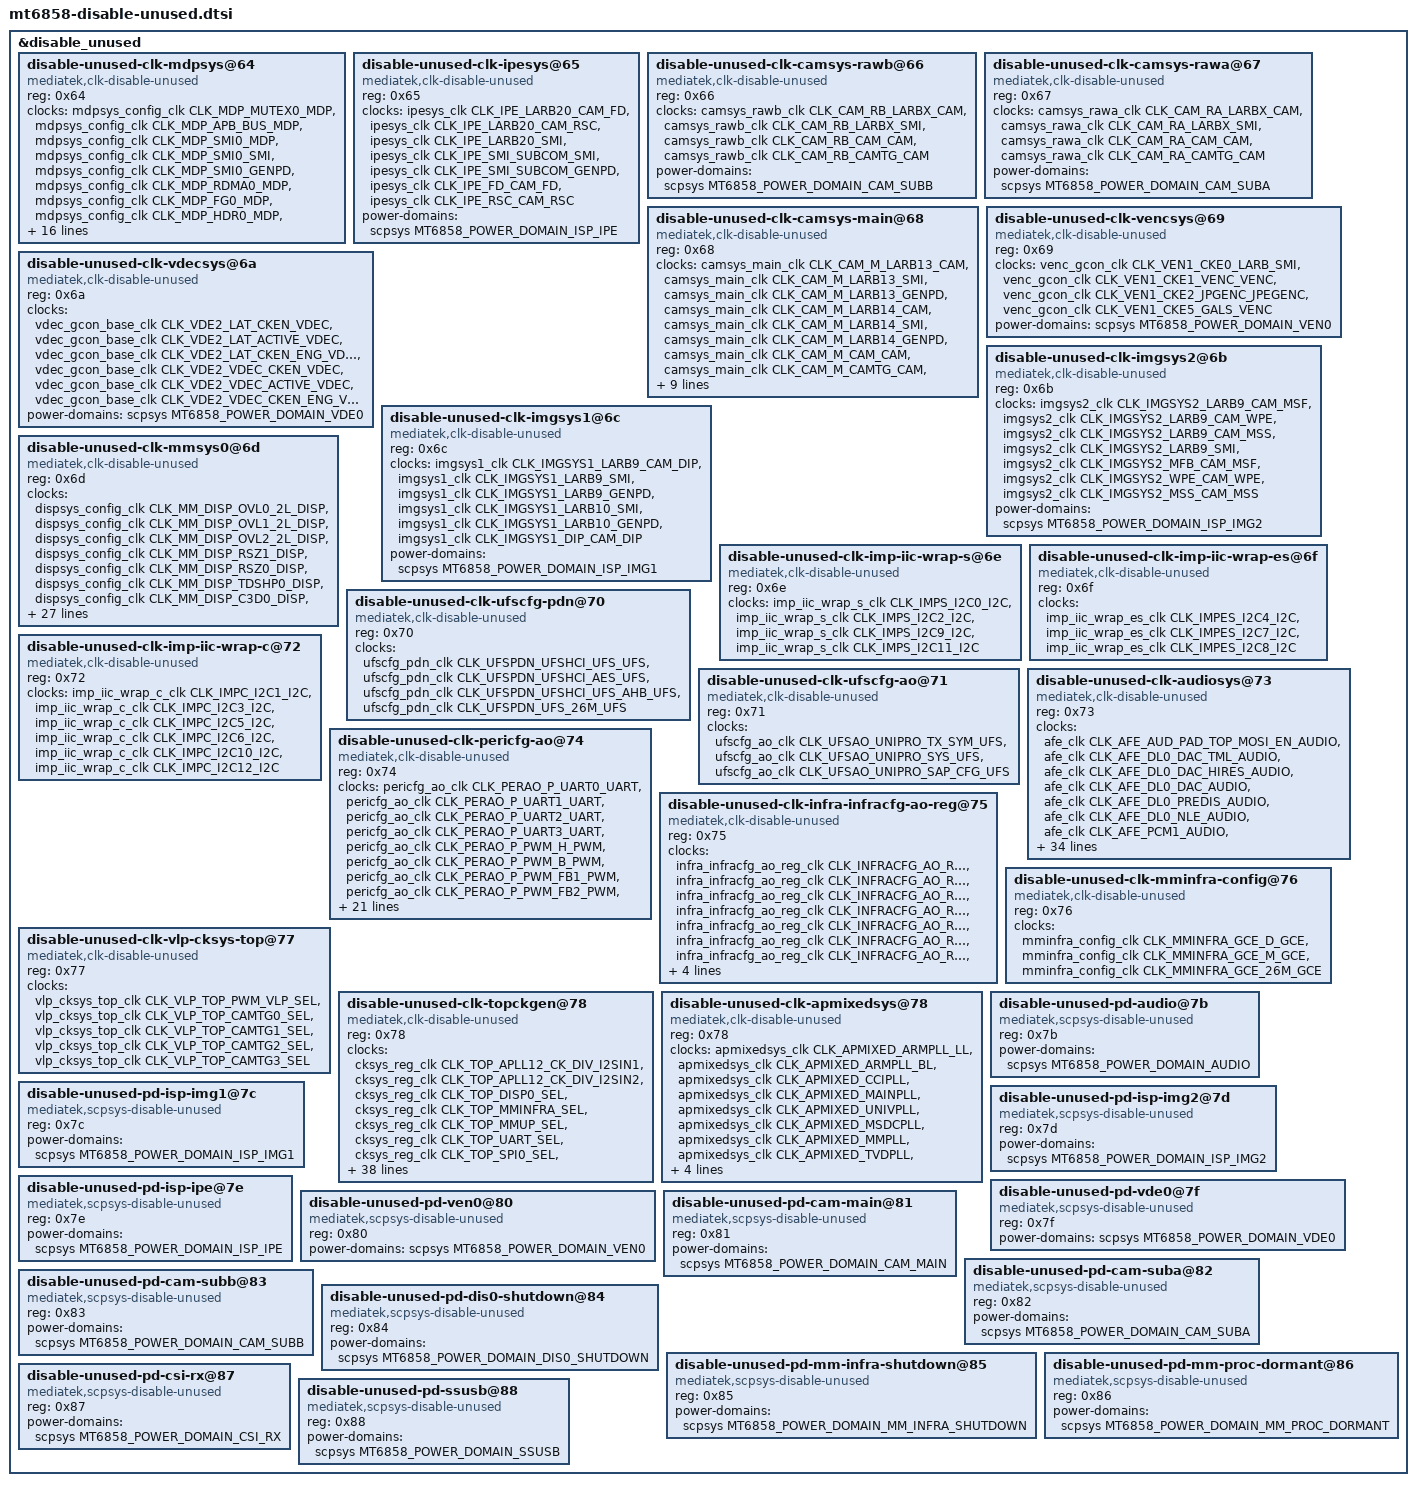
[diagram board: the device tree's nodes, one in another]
// SPDX-License-Identifier: (GPL-2.0 OR MIT)
/*
 * Copyright (C) 2025 MediaTek Inc.
 * Author: KY Liu <ky.liu@mediatek.com>
 */

&disable_unused {
	status = "okay";
	disable-unused-clk-mdpsys@64 {
		compatible = "mediatek,clk-disable-unused";
		reg = <0x64>;
		clocks =
			<&mdpsys_config_clk CLK_MDP_MUTEX0_MDP>,
			<&mdpsys_config_clk CLK_MDP_APB_BUS_MDP>,
			<&mdpsys_config_clk CLK_MDP_SMI0_MDP>,
			<&mdpsys_config_clk CLK_MDP_SMI0_SMI>,
			<&mdpsys_config_clk CLK_MDP_SMI0_GENPD>,
			<&mdpsys_config_clk CLK_MDP_RDMA0_MDP>,
			<&mdpsys_config_clk CLK_MDP_FG0_MDP>,
			<&mdpsys_config_clk CLK_MDP_HDR0_MDP>,
			<&mdpsys_config_clk CLK_MDP_AAL0_MDP>,
			<&mdpsys_config_clk CLK_MDP_RSZ0_MDP>,
			<&mdpsys_config_clk CLK_MDP_TDSHP0_MDP>,
			<&mdpsys_config_clk CLK_MDP_COLOR0_MDP>,
			<&mdpsys_config_clk CLK_MDP_WROT0_MDP>,
			<&mdpsys_config_clk CLK_MDP_FAKE_ENG0_MDP>,
			<&mdpsys_config_clk CLK_MDP_DLI_ASYNC0_MDP>,
			<&mdpsys_config_clk CLK_MDP_RSZ2_MDP>,
			<&mdpsys_config_clk CLK_MDP_WROT2_MDP>,
			<&mdpsys_config_clk CLK_MDP_DLO_ASYNC0_MDP>,
			<&mdpsys_config_clk CLK_MDP_FMM_IMG_DL_ASYNC0_MDP>,
			<&mdpsys_config_clk CLK_MDP_FMM_IMG_DL_ASYNC1_MDP>,
			<&mdpsys_config_clk CLK_MDP_FIMG_IMG_DL_ASYNC0_MDP>,
			<&mdpsys_config_clk CLK_MDP_FIMG_IMG_DL_ASYNC1_MDP>;
		power-domains = <&scpsys MT6858_POWER_DOMAIN_DIS0_SHUTDOWN>;
	};

	disable-unused-clk-ipesys@65 {
		compatible = "mediatek,clk-disable-unused";
		reg = <0x65>;
		clocks =
			<&ipesys_clk CLK_IPE_LARB20_CAM_FD>,
			<&ipesys_clk CLK_IPE_LARB20_CAM_RSC>,
			<&ipesys_clk CLK_IPE_LARB20_SMI>,
			<&ipesys_clk CLK_IPE_SMI_SUBCOM_SMI>,
			<&ipesys_clk CLK_IPE_SMI_SUBCOM_GENPD>,
			<&ipesys_clk CLK_IPE_FD_CAM_FD>,
			<&ipesys_clk CLK_IPE_RSC_CAM_RSC>;
		power-domains = <&scpsys MT6858_POWER_DOMAIN_ISP_IPE>;
	};

	disable-unused-clk-camsys-rawb@66 {
		compatible = "mediatek,clk-disable-unused";
		reg = <0x66>;
		clocks =
			<&camsys_rawb_clk CLK_CAM_RB_LARBX_CAM>,
			<&camsys_rawb_clk CLK_CAM_RB_LARBX_SMI>,
			<&camsys_rawb_clk CLK_CAM_RB_CAM_CAM>,
			<&camsys_rawb_clk CLK_CAM_RB_CAMTG_CAM>;
		power-domains = <&scpsys MT6858_POWER_DOMAIN_CAM_SUBB>;
	};

	disable-unused-clk-camsys-rawa@67 {
		compatible = "mediatek,clk-disable-unused";
		reg = <0x67>;
		clocks =
			<&camsys_rawa_clk CLK_CAM_RA_LARBX_CAM>,
			<&camsys_rawa_clk CLK_CAM_RA_LARBX_SMI>,
			<&camsys_rawa_clk CLK_CAM_RA_CAM_CAM>,
			<&camsys_rawa_clk CLK_CAM_RA_CAMTG_CAM>;
		power-domains = <&scpsys MT6858_POWER_DOMAIN_CAM_SUBA>;
	};

	disable-unused-clk-camsys-main@68 {
		compatible = "mediatek,clk-disable-unused";
		reg = <0x68>;
		clocks =
			<&camsys_main_clk CLK_CAM_M_LARB13_CAM>,
			<&camsys_main_clk CLK_CAM_M_LARB13_SMI>,
			<&camsys_main_clk CLK_CAM_M_LARB13_GENPD>,
			<&camsys_main_clk CLK_CAM_M_LARB14_CAM>,
			<&camsys_main_clk CLK_CAM_M_LARB14_SMI>,
			<&camsys_main_clk CLK_CAM_M_LARB14_GENPD>,
			<&camsys_main_clk CLK_CAM_M_CAM_CAM>,
			<&camsys_main_clk CLK_CAM_M_CAMTG_CAM>,
			<&camsys_main_clk CLK_CAM_M_SENINF_CAM>,
			<&camsys_main_clk CLK_CAM_M_CAMSV1_CAM>,
			<&camsys_main_clk CLK_CAM_M_CAMSV2_CAM>,
			<&camsys_main_clk CLK_CAM_M_CAMSV3_CAM>,
			<&camsys_main_clk CLK_CAM_M_CAM2MM_GALS_CAM>,
			<&camsys_main_clk CLK_CAM_M_CAM2MM_GALS_GENPD>,
			<&camsys_main_clk CLK_CAM_M_PDA_PDA>;
		power-domains = <&scpsys MT6858_POWER_DOMAIN_CAM_MAIN>;
	};

	disable-unused-clk-vencsys@69 {
		compatible = "mediatek,clk-disable-unused";
		reg = <0x69>;
		clocks =
			<&venc_gcon_clk CLK_VEN1_CKE0_LARB_SMI>,
			<&venc_gcon_clk CLK_VEN1_CKE1_VENC_VENC>,
			<&venc_gcon_clk CLK_VEN1_CKE2_JPGENC_JPEGENC>,
			<&venc_gcon_clk CLK_VEN1_CKE5_GALS_VENC>;
		power-domains = <&scpsys MT6858_POWER_DOMAIN_VEN0>;
	};

	disable-unused-clk-vdecsys@6a {
		compatible = "mediatek,clk-disable-unused";
		reg = <0x6a>;
		clocks =
			<&vdec_gcon_base_clk CLK_VDE2_LAT_CKEN_VDEC>,
			<&vdec_gcon_base_clk CLK_VDE2_LAT_ACTIVE_VDEC>,
			<&vdec_gcon_base_clk CLK_VDE2_LAT_CKEN_ENG_VDEC>,
			<&vdec_gcon_base_clk CLK_VDE2_VDEC_CKEN_VDEC>,
			<&vdec_gcon_base_clk CLK_VDE2_VDEC_ACTIVE_VDEC>,
			<&vdec_gcon_base_clk CLK_VDE2_VDEC_CKEN_ENG_VDEC>;
		power-domains = <&scpsys MT6858_POWER_DOMAIN_VDE0>;
	};

	disable-unused-clk-imgsys2@6b {
		compatible = "mediatek,clk-disable-unused";
		reg = <0x6b>;
		clocks =
			<&imgsys2_clk CLK_IMGSYS2_LARB9_CAM_MSF>,
			<&imgsys2_clk CLK_IMGSYS2_LARB9_CAM_WPE>,
			<&imgsys2_clk CLK_IMGSYS2_LARB9_CAM_MSS>,
			<&imgsys2_clk CLK_IMGSYS2_LARB9_SMI>,
			<&imgsys2_clk CLK_IMGSYS2_MFB_CAM_MSF>,
			<&imgsys2_clk CLK_IMGSYS2_WPE_CAM_WPE>,
			<&imgsys2_clk CLK_IMGSYS2_MSS_CAM_MSS>;
		power-domains = <&scpsys MT6858_POWER_DOMAIN_ISP_IMG2>;
	};

	disable-unused-clk-imgsys1@6c {
		compatible = "mediatek,clk-disable-unused";
		reg = <0x6c>;
		clocks =
			<&imgsys1_clk CLK_IMGSYS1_LARB9_CAM_DIP>,
			<&imgsys1_clk CLK_IMGSYS1_LARB9_SMI>,
			<&imgsys1_clk CLK_IMGSYS1_LARB9_GENPD>,
			<&imgsys1_clk CLK_IMGSYS1_LARB10_SMI>,
			<&imgsys1_clk CLK_IMGSYS1_LARB10_GENPD>,
			<&imgsys1_clk CLK_IMGSYS1_DIP_CAM_DIP>;
		power-domains = <&scpsys MT6858_POWER_DOMAIN_ISP_IMG1>;
	};

	disable-unused-clk-mmsys0@6d {
		compatible = "mediatek,clk-disable-unused";
		reg = <0x6d>;
		clocks =
			<&dispsys_config_clk CLK_MM_DISP_OVL0_2L_DISP>,
			<&dispsys_config_clk CLK_MM_DISP_OVL1_2L_DISP>,
			<&dispsys_config_clk CLK_MM_DISP_OVL2_2L_DISP>,
			<&dispsys_config_clk CLK_MM_DISP_RSZ1_DISP>,
			<&dispsys_config_clk CLK_MM_DISP_RSZ0_DISP>,
			<&dispsys_config_clk CLK_MM_DISP_TDSHP0_DISP>,
			<&dispsys_config_clk CLK_MM_DISP_C3D0_DISP>,
			<&dispsys_config_clk CLK_MM_DISP_COLOR0_DISP>,
			<&dispsys_config_clk CLK_MM_DISP_CCORR0_DISP>,
			<&dispsys_config_clk CLK_MM_DISP_CCORR1_DISP>,
			<&dispsys_config_clk CLK_MM_DISP_AAL0_DISP>,
			<&dispsys_config_clk CLK_MM_DISP_GAMMA0_DISP>,
			<&dispsys_config_clk CLK_MM_DISP_POSTMASK0_DISP>,
			<&dispsys_config_clk CLK_MM_DISP_DITHER0_DISP>,
			<&dispsys_config_clk CLK_MM_DISP_TDSHP1_DISP>,
			<&dispsys_config_clk CLK_MM_DISP_C3D1_DISP>,
			<&dispsys_config_clk CLK_MM_DISP_CCORR2_DISP>,
			<&dispsys_config_clk CLK_MM_DISP_CCORR3_DISP>,
			<&dispsys_config_clk CLK_MM_DISP_GAMMA1_DISP>,
			<&dispsys_config_clk CLK_MM_DISP_DITHER1_DISP>,
			<&dispsys_config_clk CLK_MM_DISP_DSC_WRAP0_DISP>,
			<&dispsys_config_clk CLK_MM_DISP_DSI0_DISP>,
			<&dispsys_config_clk CLK_MM_DISP_WDMA1_DISP>,
			<&dispsys_config_clk CLK_MM_DISP_APB_BUS_DISP>,
			<&dispsys_config_clk CLK_MM_DISP_FAKE_ENG0_DISP>,
			<&dispsys_config_clk CLK_MM_DISP_FAKE_ENG1_DISP>,
			<&dispsys_config_clk CLK_MM_DISP_MUTEX0_DISP>,
			<&dispsys_config_clk CLK_MM_SMI_COMMON_DISP>,
			<&dispsys_config_clk CLK_MM_SMI_COMMON_SMI>,
			<&dispsys_config_clk CLK_MM_SMI_COMMON_GENPD>,
			<&dispsys_config_clk CLK_MM_DSI0_DISP>,
			<&dispsys_config_clk CLK_MM_26M_DISP>;
		power-domains = <&scpsys MT6858_POWER_DOMAIN_DIS0_SHUTDOWN>;
	};

	disable-unused-clk-imp-iic-wrap-s@6e {
		compatible = "mediatek,clk-disable-unused";
		reg = <0x6e>;
		clocks =
			<&imp_iic_wrap_s_clk CLK_IMPS_I2C0_I2C>,
			<&imp_iic_wrap_s_clk CLK_IMPS_I2C2_I2C>,
			<&imp_iic_wrap_s_clk CLK_IMPS_I2C9_I2C>,
			<&imp_iic_wrap_s_clk CLK_IMPS_I2C11_I2C>;
	};

	disable-unused-clk-imp-iic-wrap-es@6f {
		compatible = "mediatek,clk-disable-unused";
		reg = <0x6f>;
		clocks =
			<&imp_iic_wrap_es_clk CLK_IMPES_I2C4_I2C>,
			<&imp_iic_wrap_es_clk CLK_IMPES_I2C7_I2C>,
			<&imp_iic_wrap_es_clk CLK_IMPES_I2C8_I2C>;
	};

	disable-unused-clk-ufscfg-pdn@70 {
		compatible = "mediatek,clk-disable-unused";
		reg = <0x70>;
		clocks =
			<&ufscfg_pdn_clk CLK_UFSPDN_UFSHCI_UFS_UFS>,
			<&ufscfg_pdn_clk CLK_UFSPDN_UFSHCI_AES_UFS>,
			<&ufscfg_pdn_clk CLK_UFSPDN_UFSHCI_UFS_AHB_UFS>,
			<&ufscfg_pdn_clk CLK_UFSPDN_UFS_26M_UFS>;
	};

	disable-unused-clk-ufscfg-ao@71 {
		compatible = "mediatek,clk-disable-unused";
		reg = <0x71>;
		clocks =
			<&ufscfg_ao_clk CLK_UFSAO_UNIPRO_TX_SYM_UFS>,
			<&ufscfg_ao_clk CLK_UFSAO_UNIPRO_SYS_UFS>,
			<&ufscfg_ao_clk CLK_UFSAO_UNIPRO_SAP_CFG_UFS>;
	};

	disable-unused-clk-imp-iic-wrap-c@72 {
		compatible = "mediatek,clk-disable-unused";
		reg = <0x72>;
		clocks =
			<&imp_iic_wrap_c_clk CLK_IMPC_I2C1_I2C>,
			<&imp_iic_wrap_c_clk CLK_IMPC_I2C3_I2C>,
			<&imp_iic_wrap_c_clk CLK_IMPC_I2C5_I2C>,
			<&imp_iic_wrap_c_clk CLK_IMPC_I2C6_I2C>,
			<&imp_iic_wrap_c_clk CLK_IMPC_I2C10_I2C>,
			<&imp_iic_wrap_c_clk CLK_IMPC_I2C12_I2C>;
	};

	disable-unused-clk-audiosys@73 {
		compatible = "mediatek,clk-disable-unused";
		reg = <0x73>;
		clocks =
			<&afe_clk CLK_AFE_AUD_PAD_TOP_MOSI_EN_AUDIO>,
			<&afe_clk CLK_AFE_DL0_DAC_TML_AUDIO>,
			<&afe_clk CLK_AFE_DL0_DAC_HIRES_AUDIO>,
			<&afe_clk CLK_AFE_DL0_DAC_AUDIO>,
			<&afe_clk CLK_AFE_DL0_PREDIS_AUDIO>,
			<&afe_clk CLK_AFE_DL0_NLE_AUDIO>,
			<&afe_clk CLK_AFE_PCM1_AUDIO>,
			<&afe_clk CLK_AFE_PCM0_AUDIO>,
			<&afe_clk CLK_AFE_CM1_AUDIO>,
			<&afe_clk CLK_AFE_CM0_AUDIO>,
			<&afe_clk CLK_AFE_STF_AUDIO>,
			<&afe_clk CLK_AFE_HW_GAIN23_AUDIO>,
			<&afe_clk CLK_AFE_HW_GAIN01_AUDIO>,
			<&afe_clk CLK_AFE_UL1_ADC_HIRES_TML_AUDIO>,
			<&afe_clk CLK_AFE_UL1_ADC_HIRES_AUDIO>,
			<&afe_clk CLK_AFE_UL1_TML_AUDIO>,
			<&afe_clk CLK_AFE_UL1_ADC_AUDIO>,
			<&afe_clk CLK_AFE_UL0_ADC_HIRES_TML_AUDIO>,
			<&afe_clk CLK_AFE_UL0_ADC_HIRES_AUDIO>,
			<&afe_clk CLK_AFE_UL0_TML_AUDIO>,
			<&afe_clk CLK_AFE_UL0_ADC_AUDIO>,
			<&afe_clk CLK_AFE_ETDM_IN4_AUDIO>,
			<&afe_clk CLK_AFE_ETDM_IN2_AUDIO>,
			<&afe_clk CLK_AFE_ETDM_IN1_AUDIO>,
			<&afe_clk CLK_AFE_ETDM_OUT4_AUDIO>,
			<&afe_clk CLK_AFE_ETDM_OUT2_AUDIO>,
			<&afe_clk CLK_AFE_ETDM_OUT1_AUDIO>,
			<&afe_clk CLK_AFE_GENERAL3_ASRC_AUDIO>,
			<&afe_clk CLK_AFE_GENERAL2_ASRC_AUDIO>,
			<&afe_clk CLK_AFE_GENERAL1_ASRC_AUDIO>,
			<&afe_clk CLK_AFE_GENERAL0_ASRC_AUDIO>,
			<&afe_clk CLK_AFE_CONNSYS_I2S_ASRC_AUDIO>,
			<&afe_clk CLK_AFE_AUDIO_HOPPING_AUDIO>,
			<&afe_clk CLK_AFE_AUDIO_F26M_AUDIO>,
			<&afe_clk CLK_AFE_APLL1_AUDIO>,
			<&afe_clk CLK_AFE_APLL2_AUDIO>,
			<&afe_clk CLK_AFE_H208M_AUDIO>,
			<&afe_clk CLK_AFE_APLL_TUNER2_AUDIO>,
			<&afe_clk CLK_AFE_APLL_TUNER1_AUDIO>;
		power-domains = <&scpsys MT6858_POWER_DOMAIN_AUDIO>;
	};

	disable-unused-clk-pericfg-ao@74 {
		compatible = "mediatek,clk-disable-unused";
		reg = <0x74>;
		clocks =
			<&pericfg_ao_clk CLK_PERAO_P_UART0_UART>,
			<&pericfg_ao_clk CLK_PERAO_P_UART1_UART>,
			<&pericfg_ao_clk CLK_PERAO_P_UART2_UART>,
			<&pericfg_ao_clk CLK_PERAO_P_UART3_UART>,
			<&pericfg_ao_clk CLK_PERAO_P_PWM_H_PWM>,
			<&pericfg_ao_clk CLK_PERAO_P_PWM_B_PWM>,
			<&pericfg_ao_clk CLK_PERAO_P_PWM_FB1_PWM>,
			<&pericfg_ao_clk CLK_PERAO_P_PWM_FB2_PWM>,
			<&pericfg_ao_clk CLK_PERAO_P_PWM_FB3_PWM>,
			<&pericfg_ao_clk CLK_PERAO_P_PWM_FB4_PWM>,
			<&pericfg_ao_clk CLK_PERAO_P_DISP_PWM0_DISP_PWM_0>,
			<&pericfg_ao_clk CLK_PERAO_P_DISP_PWM1_DISP_PWM_1>,
			<&pericfg_ao_clk CLK_PERAO_P_SPI0_B_SPI>,
			<&pericfg_ao_clk CLK_PERAO_P_SPI1_B_SPI>,
			<&pericfg_ao_clk CLK_PERAO_P_SPI2_B_SPI>,
			<&pericfg_ao_clk CLK_PERAO_P_SPI3_B_SPI>,
			<&pericfg_ao_clk CLK_PERAO_P_SPI4_B_SPI>,
			<&pericfg_ao_clk CLK_PERAO_P_SPI5_B_SPI>,
			<&pericfg_ao_clk CLK_PERAO_P_SPI6_B_SPI>,
			<&pericfg_ao_clk CLK_PERAO_P_SPI7_B_SPI>,
			<&pericfg_ao_clk CLK_PERAO_P_DMA_B_UART>,
			<&pericfg_ao_clk CLK_PERAO_P_DMA_B_I2C>,
			<&pericfg_ao_clk CLK_PERAO_P_MSDC1_MSDC>,
			<&pericfg_ao_clk CLK_PERAO_P_MSDC1_H_MSDC>,
			<&pericfg_ao_clk CLK_PERAO_P_MSDC1_MST_F_MSDC>,
			<&pericfg_ao_clk CLK_PERAO_P_MSDC1_SLV_H_MSDC>,
			<&pericfg_ao_clk CLK_PERAO_P_AUDIO0_AUDIO>,
			<&pericfg_ao_clk CLK_PERAO_P_AUDIO1_AUDIO>,
			<&pericfg_ao_clk CLK_PERAO_P_AUDIO2_AUDIO>;
	};

	disable-unused-clk-infra-infracfg-ao-reg@75 {
		compatible = "mediatek,clk-disable-unused";
		reg = <0x75>;
		clocks =
			<&infra_infracfg_ao_reg_clk CLK_INFRACFG_AO_REG_CCIF1_AP_CCCI>,
			<&infra_infracfg_ao_reg_clk CLK_INFRACFG_AO_REG_CCIF1_MD_CCCI>,
			<&infra_infracfg_ao_reg_clk CLK_INFRACFG_AO_REG_CCIF_AP_CCCI>,
			<&infra_infracfg_ao_reg_clk CLK_INFRACFG_AO_REG_CCIF_MD_CCCI>,
			<&infra_infracfg_ao_reg_clk CLK_INFRACFG_AO_REG_CLDMA_BCLK_DPMAIF>,
			<&infra_infracfg_ao_reg_clk CLK_INFRACFG_AO_REG_CCIF5_MD_CCCI>,
			<&infra_infracfg_ao_reg_clk CLK_INFRACFG_AO_REG_CCIF2_AP_CCCI>,
			<&infra_infracfg_ao_reg_clk CLK_INFRACFG_AO_REG_CCIF2_MD_CCCI>,
			<&infra_infracfg_ao_reg_clk CLK_INFRACFG_AO_REG_DPMAIF_MAIN_DPMAIF>,
			<&infra_infracfg_ao_reg_clk CLK_INFRACFG_AO_REG_CCIF4_MD_CCCI>,
			<&infra_infracfg_ao_reg_clk CLK_INFRACFG_AO_REG_RG_MMW_DPMAIF26M_DPMAIF>;
	};


	disable-unused-clk-mminfra-config@76 {
		compatible = "mediatek,clk-disable-unused";
		reg = <0x76>;
		clocks =
			<&mminfra_config_clk CLK_MMINFRA_GCE_D_GCE>,
			<&mminfra_config_clk CLK_MMINFRA_GCE_M_GCE>,
			<&mminfra_config_clk CLK_MMINFRA_GCE_26M_GCE>;
	};

	disable-unused-clk-vlp-cksys-top@77 {
		compatible = "mediatek,clk-disable-unused";
		reg = <0x77>;
		clocks =
			<&vlp_cksys_top_clk CLK_VLP_TOP_PWM_VLP_SEL>,
			<&vlp_cksys_top_clk CLK_VLP_TOP_CAMTG0_SEL>,
			<&vlp_cksys_top_clk CLK_VLP_TOP_CAMTG1_SEL>,
			<&vlp_cksys_top_clk CLK_VLP_TOP_CAMTG2_SEL>,
			<&vlp_cksys_top_clk CLK_VLP_TOP_CAMTG3_SEL>;
	};

	disable-unused-clk-topckgen@78 {
		compatible = "mediatek,clk-disable-unused";
		reg = <0x78>;
		clocks =
			<&cksys_reg_clk CLK_TOP_APLL12_CK_DIV_I2SIN1>,
			<&cksys_reg_clk CLK_TOP_APLL12_CK_DIV_I2SIN2>,
			<&cksys_reg_clk CLK_TOP_DISP0_SEL>,
			<&cksys_reg_clk CLK_TOP_MMINFRA_SEL>,
			<&cksys_reg_clk CLK_TOP_MMUP_SEL>,
			<&cksys_reg_clk CLK_TOP_UART_SEL>,
			<&cksys_reg_clk CLK_TOP_SPI0_SEL>,
			<&cksys_reg_clk CLK_TOP_SPI1_SEL>,
			<&cksys_reg_clk CLK_TOP_SPI2_SEL>,
			<&cksys_reg_clk CLK_TOP_SPI3_SEL>,
			<&cksys_reg_clk CLK_TOP_SPI4_SEL>,
			<&cksys_reg_clk CLK_TOP_SPI5_SEL>,
			<&cksys_reg_clk CLK_TOP_SPI6_SEL>,
			<&cksys_reg_clk CLK_TOP_SPI7_SEL>,
			<&cksys_reg_clk CLK_TOP_MSDC_MACRO_1P_SEL>,
			<&cksys_reg_clk CLK_TOP_MSDC30_1_SEL>,
			<&cksys_reg_clk CLK_TOP_MSDC30_1_HCLK_SEL>,
			<&cksys_reg_clk CLK_TOP_AUD_INTBUS_SEL>,
			<&cksys_reg_clk CLK_TOP_DISP_PWM_SEL>,
			<&cksys_reg_clk CLK_TOP_USB_TOP_SEL>,
			<&cksys_reg_clk CLK_TOP_USB_XHCI_SEL>,
			<&cksys_reg_clk CLK_TOP_I2C_SEL>,
			<&cksys_reg_clk CLK_TOP_SENINF_SEL>,
			<&cksys_reg_clk CLK_TOP_SENINF1_SEL>,
			<&cksys_reg_clk CLK_TOP_SENINF2_SEL>,
			<&cksys_reg_clk CLK_TOP_AUD_ENGEN1_SEL>,
			<&cksys_reg_clk CLK_TOP_AUD_ENGEN2_SEL>,
			<&cksys_reg_clk CLK_TOP_AES_UFSFDE_SEL>,
			<&cksys_reg_clk CLK_TOP_UFS_SEL>,
			<&cksys_reg_clk CLK_TOP_AUD_1_SEL>,
			<&cksys_reg_clk CLK_TOP_AUD_2_SEL>,
			<&cksys_reg_clk CLK_TOP_DPMAIF_MAIN_SEL>,
			<&cksys_reg_clk CLK_TOP_VENC_SEL>,
			<&cksys_reg_clk CLK_TOP_VDEC_SEL>,
			<&cksys_reg_clk CLK_TOP_PWM_SEL>,
			<&cksys_reg_clk CLK_TOP_AUDIO_H_SEL>,
			<&cksys_reg_clk CLK_TOP_DSI_OCC_SEL>,
			<&cksys_reg_clk CLK_TOP_IMG1_SEL>,
			<&cksys_reg_clk CLK_TOP_IPE_SEL>,
			<&cksys_reg_clk CLK_TOP_CAM_SEL>,
			<&cksys_reg_clk CLK_TOP_CAMTM_SEL>,
			<&cksys_reg_clk CLK_TOP_UNIPLL_SES_SEL>,
			<&cksys_reg_clk CLK_TOP_USB_FRMCNT_SEL>,
			<&cksys_reg_clk CLK_TOP_APLL_I2SIN1_MCK_SEL>,
			<&cksys_reg_clk CLK_TOP_APLL_I2SIN2_MCK_SEL>;
	};

	disable-unused-clk-apmixedsys@78 {
		compatible = "mediatek,clk-disable-unused";
		reg = <0x78>;
		clocks =
			<&apmixedsys_clk CLK_APMIXED_ARMPLL_LL>,
			<&apmixedsys_clk CLK_APMIXED_ARMPLL_BL>,
			<&apmixedsys_clk CLK_APMIXED_CCIPLL>,
			<&apmixedsys_clk CLK_APMIXED_MAINPLL>,
			<&apmixedsys_clk CLK_APMIXED_UNIVPLL>,
			<&apmixedsys_clk CLK_APMIXED_MSDCPLL>,
			<&apmixedsys_clk CLK_APMIXED_MMPLL>,
			<&apmixedsys_clk CLK_APMIXED_TVDPLL>,
			<&apmixedsys_clk CLK_APMIXED_EMIPLL>,
			<&apmixedsys_clk CLK_APMIXED_ADSPPLL>,
			<&apmixedsys_clk CLK_APMIXED_APLL1>,
			<&apmixedsys_clk CLK_APMIXED_APLL2>;
	};

	disable-unused-pd-audio@7b {
		compatible = "mediatek,scpsys-disable-unused";
		reg = <0x7b>;
		power-domains = <&scpsys MT6858_POWER_DOMAIN_AUDIO>;
	};

	disable-unused-pd-isp-img1@7c {
		compatible = "mediatek,scpsys-disable-unused";
		reg = <0x7c>;
		power-domains = <&scpsys MT6858_POWER_DOMAIN_ISP_IMG1>;
	};

	disable-unused-pd-isp-img2@7d {
		compatible = "mediatek,scpsys-disable-unused";
		reg = <0x7d>;
		power-domains = <&scpsys MT6858_POWER_DOMAIN_ISP_IMG2>;
	};

	disable-unused-pd-isp-ipe@7e {
		compatible = "mediatek,scpsys-disable-unused";
		reg = <0x7e>;
		power-domains = <&scpsys MT6858_POWER_DOMAIN_ISP_IPE>;
	};

	disable-unused-pd-vde0@7f {
		compatible = "mediatek,scpsys-disable-unused";
		reg = <0x7f>;
		power-domains = <&scpsys MT6858_POWER_DOMAIN_VDE0>;
	};

	disable-unused-pd-ven0@80 {
		compatible = "mediatek,scpsys-disable-unused";
		reg = <0x80>;
		power-domains = <&scpsys MT6858_POWER_DOMAIN_VEN0>;
	};

	disable-unused-pd-cam-main@81 {
		compatible = "mediatek,scpsys-disable-unused";
		reg = <0x81>;
		power-domains = <&scpsys MT6858_POWER_DOMAIN_CAM_MAIN>;
	};

	disable-unused-pd-cam-suba@82 {
		compatible = "mediatek,scpsys-disable-unused";
		reg = <0x82>;
		power-domains = <&scpsys MT6858_POWER_DOMAIN_CAM_SUBA>;
	};

	disable-unused-pd-cam-subb@83 {
		compatible = "mediatek,scpsys-disable-unused";
		reg = <0x83>;
		power-domains = <&scpsys MT6858_POWER_DOMAIN_CAM_SUBB>;
	};

	disable-unused-pd-dis0-shutdown@84 {
		compatible = "mediatek,scpsys-disable-unused";
		reg = <0x84>;
		power-domains = <&scpsys MT6858_POWER_DOMAIN_DIS0_SHUTDOWN>;
	};

	disable-unused-pd-mm-infra-shutdown@85 {
		compatible = "mediatek,scpsys-disable-unused";
		reg = <0x85>;
		power-domains = <&scpsys MT6858_POWER_DOMAIN_MM_INFRA_SHUTDOWN>;
	};

	disable-unused-pd-mm-proc-dormant@86 {
		compatible = "mediatek,scpsys-disable-unused";
		reg = <0x86>;
		power-domains = <&scpsys MT6858_POWER_DOMAIN_MM_PROC_DORMANT>;
	};

	disable-unused-pd-csi-rx@87 {
		compatible = "mediatek,scpsys-disable-unused";
		reg = <0x87>;
		power-domains = <&scpsys MT6858_POWER_DOMAIN_CSI_RX>;
	};

	disable-unused-pd-ssusb@88 {
		compatible = "mediatek,scpsys-disable-unused";
		reg = <0x88>;
		power-domains = <&scpsys MT6858_POWER_DOMAIN_SSUSB>;
	};
};
